# HDSC_HC32F005 register map
Vendor: HDSC Co.Ltd; Series: ARMCM0P; File version: 1.2
CPU: CM0 r0p0, little endian, no MPU, no FPU, 3 interrupt priority bits
Registers are 32-bit, read-write, reset 0x0 unless marked. A register's access mark holds for its fields unless they carry their own. Offsets are from the block's base; [hi:lo] are bit positions; {n}, {i} and the like mark numbered series.

## BGR
Base 0x40002400; alternate view of ADC
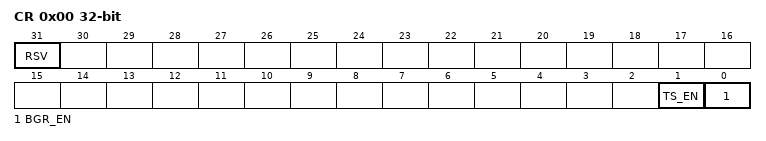
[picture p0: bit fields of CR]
0x00 CR (reset mask 0x3)
  [31] RSV, [1] TS_EN, [0] BGR_EN

## CLK_TRIM
Base 0x40001800
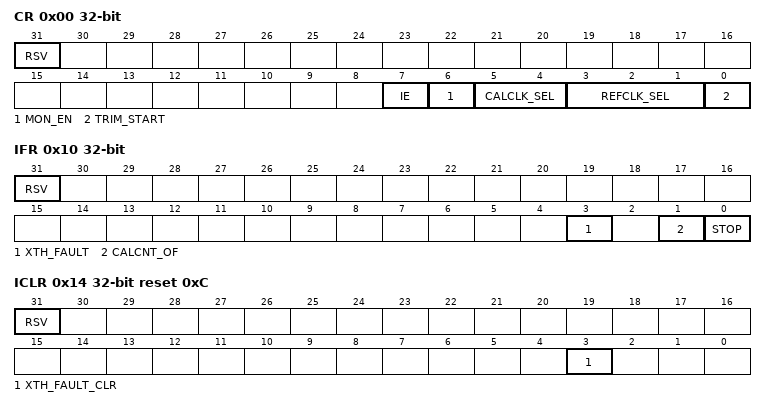
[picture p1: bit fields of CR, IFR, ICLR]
0x00 CR (reset mask 0xFF)
  [31] RSV, [7] IE, [6] MON_EN, [5:4] CALCLK_SEL, [3:1] REFCLK_SEL, [0] TRIM_START
0x04 REFCON
  [31:0] RCNTVAL
0x08 REFCNT ro
0x0C CALCNT ro
0x10 IFR ro (reset mask 0xF)
  [31] RSV, [3] XTH_FAULT, [1] CALCNT_OF, [0] STOP
0x14 ICLR reset 0xC (reset mask 0xC)
  [31] RSV, [3] XTH_FAULT_CLR
0x18 CALCON reset 0xFFFFFFFF
  [31:0] CCNTVAL

## CRC
Base 0x40020900
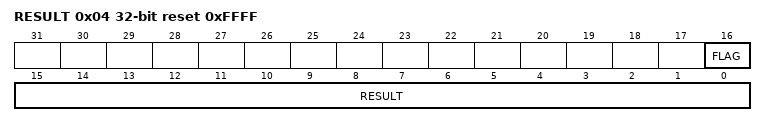
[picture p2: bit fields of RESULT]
0x04 RESULT reset 0xFFFF
  [16] FLAG ro, [15:0] RESULT
0x80 DATA wo

## DEBUG_ACTIVE
Base 0x40002038
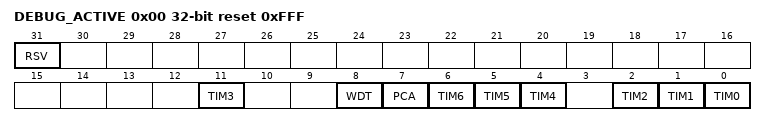
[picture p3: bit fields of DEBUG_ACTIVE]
0x00 DEBUG_ACTIVE reset 0xFFF (reset mask 0xFFF)
  [31] RSV, [11] TIM3, [8] WDT, [7] PCA, [6] TIM6, [5] TIM5, [4] TIM4, [2] TIM2, [1] TIM1, [0] TIM0

## FLASH
Base 0x40020000
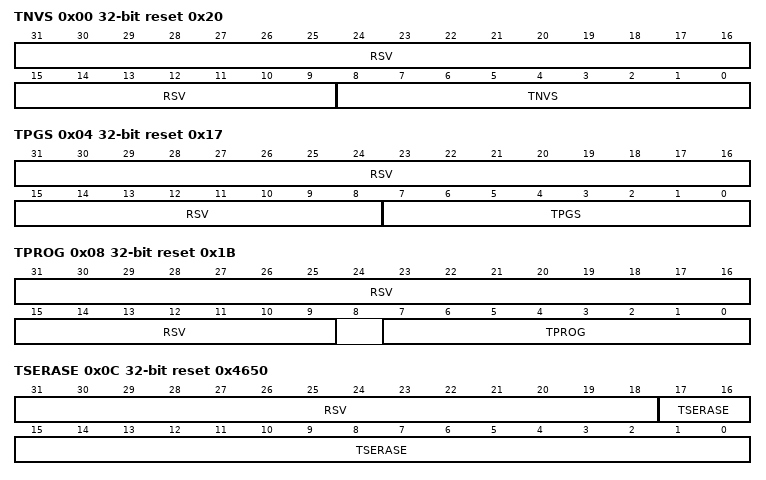
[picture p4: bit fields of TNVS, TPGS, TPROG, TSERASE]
0x00 TNVS reset 0x20 (reset mask 0x1FF)
  [31:9] RSV, [8:0] TNVS
0x04 TPGS reset 0x17 (reset mask 0xFF)
  [31:8] RSV, [7:0] TPGS
0x08 TPROG reset 0x1B (reset mask 0xFF)
  [31:9] RSV, [7:0] TPROG
0x0C TSERASE reset 0x4650 (reset mask 0x3FFFF)
  [31:18] RSV, [17:0] TSERASE
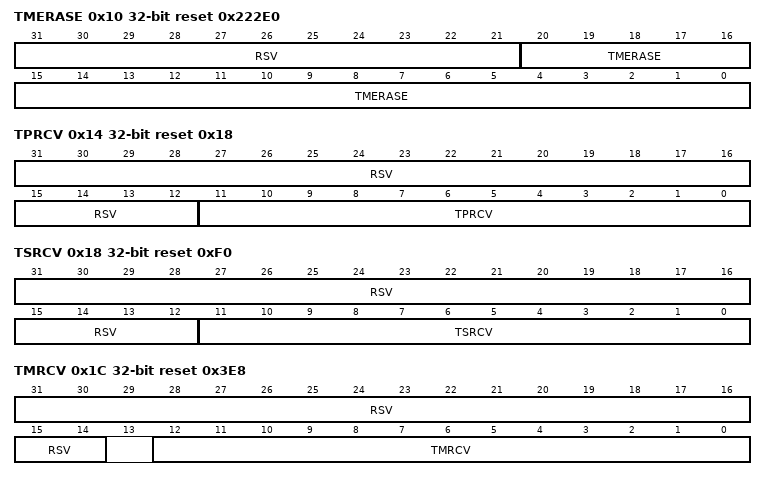
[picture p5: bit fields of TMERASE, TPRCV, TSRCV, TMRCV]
0x10 TMERASE reset 0x222E0 (reset mask 0x1FFFFF)
  [31:21] RSV, [20:0] TMERASE
0x14 TPRCV reset 0x18 (reset mask 0xFFF)
  [31:12] RSV, [11:0] TPRCV
0x18 TSRCV reset 0xF0 (reset mask 0xFFF)
  [31:12] RSV, [11:0] TSRCV
0x1C TMRCV reset 0x3E8 (reset mask 0x1FFF)
  [31:14] RSV, [12:0] TMRCV
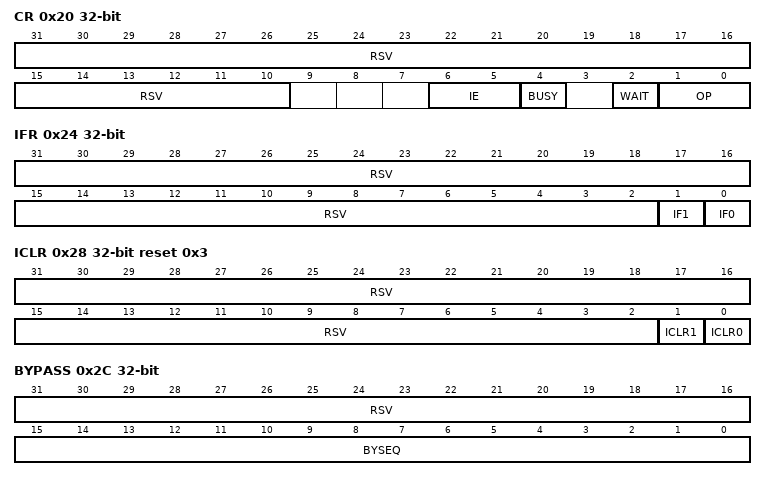
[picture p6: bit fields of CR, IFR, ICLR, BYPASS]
0x20 CR
  [31:10] RSV, [6:5] IE, [4] BUSY ro, [2] WAIT, [1:0] OP
0x24 IFR ro (reset mask 0x3)
  [31:2] RSV rw, [1] IF1, [0] IF0
0x28 ICLR wo reset 0x3
  [31:2] RSV rw, [1] ICLR1, [0] ICLR0
0x2C BYPASS wo (reset mask 0xFFFF)
  [31:16] RSV rw, [15:0] BYSEQ
0x30 SLOCK
  [15:0] SLOCK

## GPIO
Base 0x40020C00
{0x0+4i} P{i:02}_SEL (i=1..3)
  [2:0] SEL
0x50 P14_SEL
  [2:0] SEL
0x54 P15_SEL
  [2:0] SEL
{0x30+4i} P{i}_SEL (i=23..27)
  [2:0] SEL
{0x48+4i} P{i}_SEL (i=31..36)
  [2:0] SEL
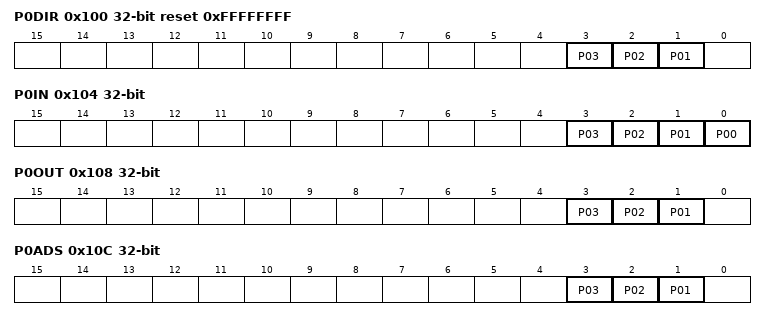
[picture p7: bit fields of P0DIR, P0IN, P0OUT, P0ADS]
0x100 P0DIR reset 0xFFFFFFFF
  [3] P03, [2] P02, [1] P01
0x104 P0IN ro
  [n] P{n:02} (n=0..3)
0x108 P0OUT
  [3] P03, [2] P02, [1] P01
0x10C P0ADS
  [3] P03, [2] P02, [1] P01
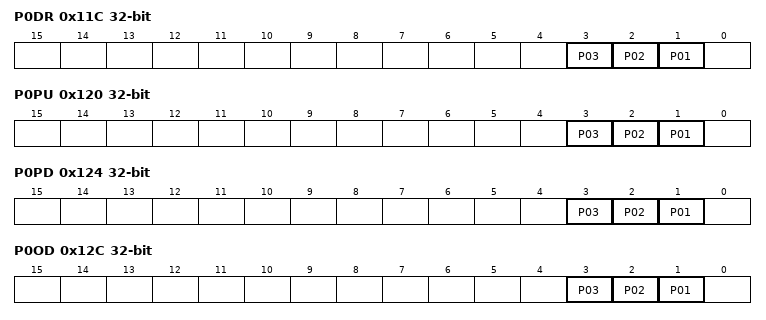
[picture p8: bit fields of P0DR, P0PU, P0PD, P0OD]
0x11C P0DR
  [3] P03, [2] P02, [1] P01
0x120 P0PU
  [3] P03, [2] P02, [1] P01
0x124 P0PD
  [3] P03, [2] P02, [1] P01
0x12C P0OD
  [3] P03, [2] P02, [1] P01
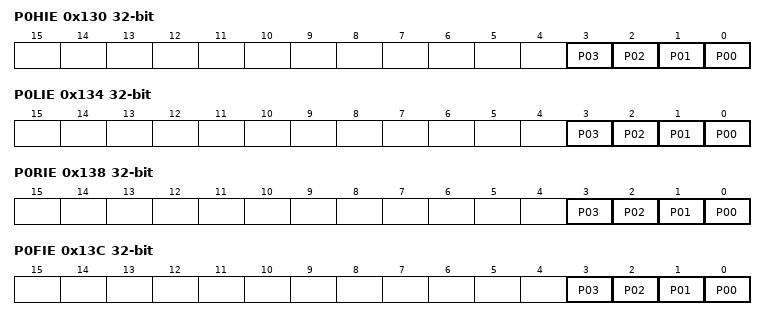
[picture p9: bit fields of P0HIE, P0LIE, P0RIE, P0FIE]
0x130 P0HIE ro
  [n] P{n:02} (n=0..3)
0x134 P0LIE ro
  [n] P{n:02} (n=0..3)
0x138 P0RIE ro
  [n] P{n:02} (n=0..3)
0x13C P0FIE ro
  [n] P{n:02} (n=0..3)
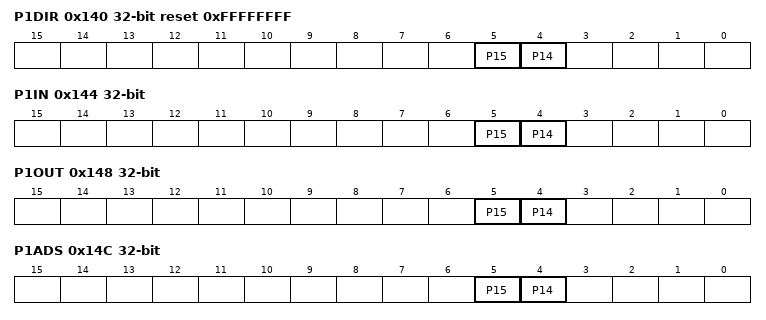
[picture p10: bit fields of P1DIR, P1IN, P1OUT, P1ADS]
0x140 P1DIR reset 0xFFFFFFFF
  [5] P15, [4] P14
0x144 P1IN ro (reset mask 0x3)
  [5] P15, [4] P14
0x148 P1OUT
  [5] P15, [4] P14
0x14C P1ADS
  [5] P15, [4] P14
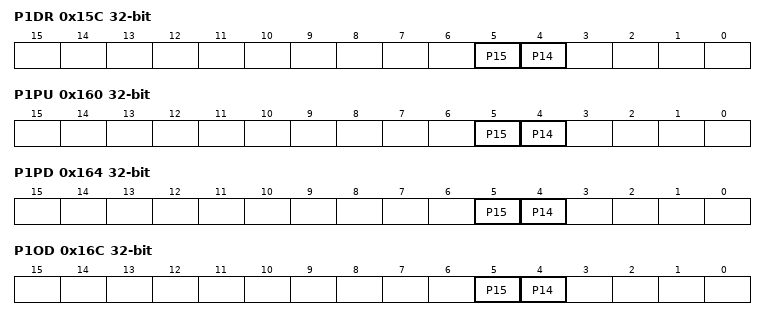
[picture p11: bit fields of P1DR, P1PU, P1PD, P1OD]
0x15C P1DR
  [5] P15, [4] P14
0x160 P1PU
  [5] P15, [4] P14
0x164 P1PD
  [5] P15, [4] P14
0x16C P1OD
  [5] P15, [4] P14
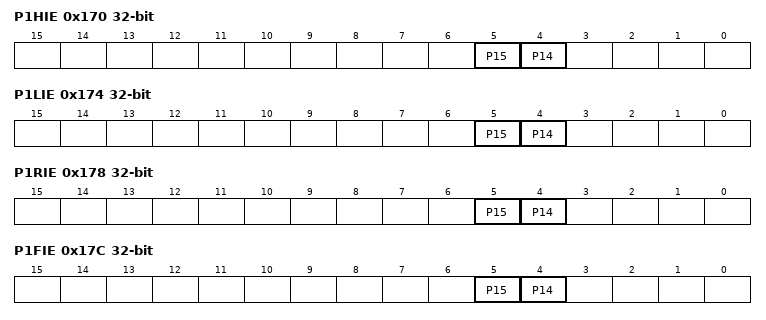
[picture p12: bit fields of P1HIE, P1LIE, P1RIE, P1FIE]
0x170 P1HIE ro (reset mask 0x3)
  [5] P15, [4] P14
0x174 P1LIE ro (reset mask 0x3)
  [5] P15, [4] P14
0x178 P1RIE ro (reset mask 0x3)
  [5] P15, [4] P14
0x17C P1FIE ro (reset mask 0x3)
  [5] P15, [4] P14
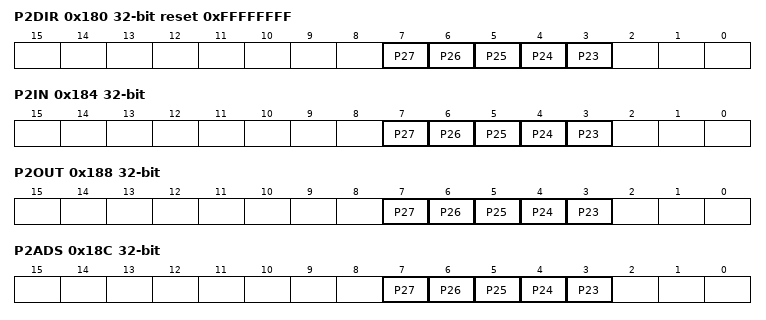
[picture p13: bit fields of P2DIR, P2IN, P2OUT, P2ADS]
0x180 P2DIR reset 0xFFFFFFFF
  [n-20] P{n} (n=23..27)
0x184 P2IN ro (reset mask 0x3)
  [n-20] P{n} (n=23..27)
0x188 P2OUT
  [n-20] P{n} (n=23..27)
0x18C P2ADS
  [n-20] P{n} (n=23..27)
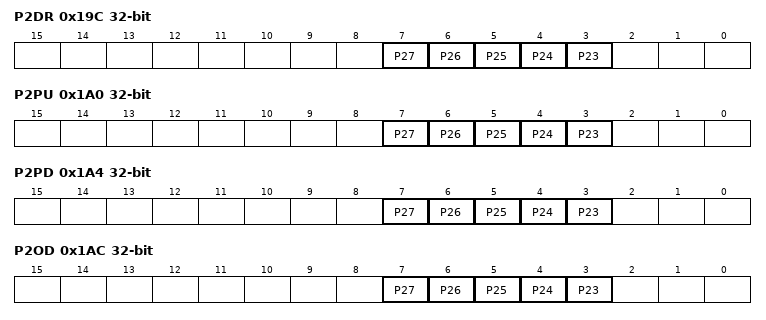
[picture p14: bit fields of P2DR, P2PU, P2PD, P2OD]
0x19C P2DR
  [n-20] P{n} (n=23..27)
0x1A0 P2PU
  [n-20] P{n} (n=23..27)
0x1A4 P2PD
  [n-20] P{n} (n=23..27)
0x1AC P2OD
  [n-20] P{n} (n=23..27)
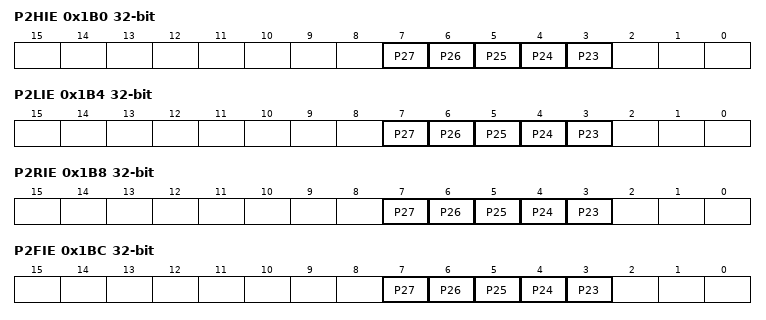
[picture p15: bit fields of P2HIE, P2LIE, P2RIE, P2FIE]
0x1B0 P2HIE ro (reset mask 0x3)
  [n-20] P{n} (n=23..27)
0x1B4 P2LIE ro (reset mask 0x3)
  [n-20] P{n} (n=23..27)
0x1B8 P2RIE ro (reset mask 0x3)
  [n-20] P{n} (n=23..27)
0x1BC P2FIE ro (reset mask 0x3)
  [n-20] P{n} (n=23..27)
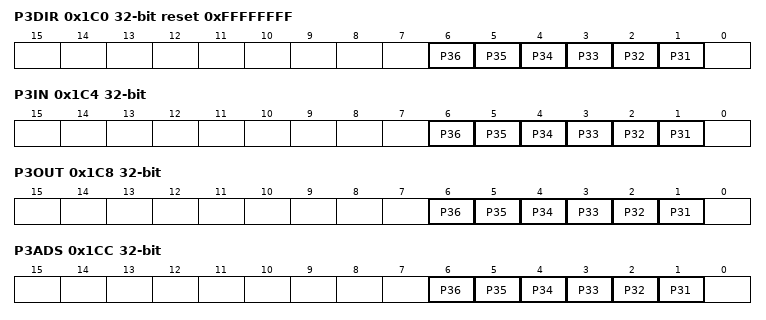
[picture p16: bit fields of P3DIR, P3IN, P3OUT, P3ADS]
0x1C0 P3DIR reset 0xFFFFFFFF
  [n-30] P{n} (n=31..36)
0x1C4 P3IN ro
  [n-30] P{n} (n=31..36)
0x1C8 P3OUT
  [n-30] P{n} (n=31..36)
0x1CC P3ADS
  [n-30] P{n} (n=31..36)
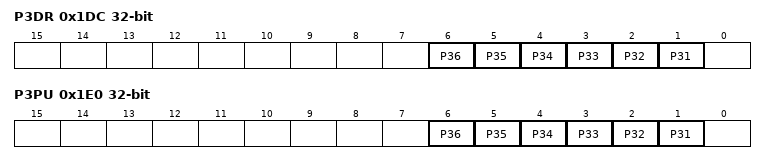
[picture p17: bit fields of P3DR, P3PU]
0x1DC P3DR
  [n-30] P{n} (n=31..36)
0x1E0 P3PU
  [n-30] P{n} (n=31..36)
0x1E4 P3PD
  [n-30] P{n} (n=31..36)
0x1EC P3OD
  [n-30] P{n} (n=31..36)
0x1F0 P3HIE ro
  [n-30] P{n} (n=31..36)
0x1F4 P3LIE ro
  [n-30] P{n} (n=31..36)
0x1F8 P3RIE ro
  [n-30] P{n} (n=31..36)
0x1FC P3FIE ro
  [n-30] P{n} (n=31..36)
0x200 P0STAT ro
  [n] P{n:02} (n=0..3)
0x210 P0ICLR ro
  [n] P{n:02} (n=0..3)
0x240 P1STAT ro (reset mask 0x3)
  [5] P15, [4] P14
0x250 P1ICLR ro (reset mask 0x3)
  [5] P15, [4] P14
0x280 P2STAT ro (reset mask 0x3)
  [n-20] P{n} (n=23..27)
0x290 P2ICLR ro (reset mask 0x3)
  [n-20] P{n} (n=23..27)
0x2C0 P3STAT ro
  [n-30] P{n} (n=31..36)
0x2D0 P3ICLR ro
  [n-30] P{n} (n=31..36)
0x300 CTRL0 reset 0x1
  [0] IESEL
0x304 CTRL1
  [14] IR_POL, [13] HCLK_EN, [12] PCLK_EN, [11:10] HCLK_SEL, [9:8] PCLK_SEL, [7:4] SSN_SEL, [3:0] EXT_CLK_SEL
0x308 CTRL2
  [2n+1:2n] PCA_CAP{n}_SEL (n=0..4)
0x30C CTRL3
  [11:10] TM6_A_SEL, [9:8] TM5_A_SEL, [7:6] TM4_A_SEL, [5:4] TM6_B_SEL, [3:2] TM5_B_SEL, [1:0] TM4_B_SEL
0x310 CTRL4
  [2n+1:2n] TM{n}_GATE_SEL (n=0..3)
